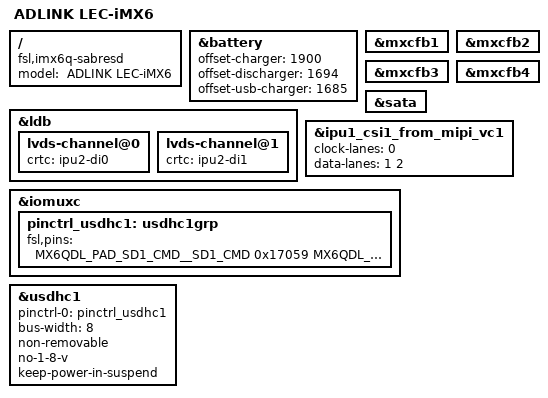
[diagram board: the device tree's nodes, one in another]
// SPDX-License-Identifier: GPL-2.0+
//
// Copyright 2012 Freescale Semiconductor, Inc.
// Copyright 2011 Linaro Ltd.

/dts-v1/;

#include "imx6q.dtsi"
#include "lec-imx6qdl.dtsi"

/ {
	model = " ADLINK LEC-iMX6";
	compatible = "fsl,imx6q-sabresd", "fsl,imx6q";
};

&battery {
	offset-charger = <1900>;
	offset-discharger = <1694>;
	offset-usb-charger = <1685>;
};

&ldb {
	lvds-channel@0 {
		crtc = "ipu2-di0";
	};

	lvds-channel@1 {
		crtc = "ipu2-di1";
	};
};

&mxcfb1 {
	status = "okay";
};

&mxcfb2 {
	status = "okay";
};

&mxcfb3 {
	status = "okay";
};

&mxcfb4 {
	status = "okay";
};

&sata {
	status = "okay";
};

&ipu1_csi1_from_mipi_vc1 {
	clock-lanes = <0>;
	data-lanes = <1 2>;
};

&iomuxc {
      pinctrl-names = "default";

	pinctrl_usdhc1: usdhc1grp {
		fsl,pins = <
			MX6QDL_PAD_SD1_CMD__SD1_CMD   		0x17059
			MX6QDL_PAD_SD1_CLK__SD1_CLK   		0x10059
			MX6QDL_PAD_SD1_DAT0__SD1_DATA0		0x17059
			MX6QDL_PAD_SD1_DAT1__SD1_DATA1		0x17059
			MX6QDL_PAD_SD1_DAT2__SD1_DATA2		0x17059
			MX6QDL_PAD_SD1_DAT3__SD1_DATA3		0x17059
			MX6QDL_PAD_NANDF_D0__SD1_DATA4		0x17059
			MX6QDL_PAD_NANDF_D1__SD1_DATA5		0x17059
			MX6QDL_PAD_NANDF_D2__SD1_DATA6		0x17059
			MX6QDL_PAD_NANDF_D3__SD1_DATA7		0x17059
		>;
	};
};

&usdhc1 {
	pinctrl-names = "default";
	pinctrl-0 = <&pinctrl_usdhc1>;
	bus-width = <8>;
	non-removable;
	no-1-8-v;
	keep-power-in-suspend;
	status = "okay";
};
